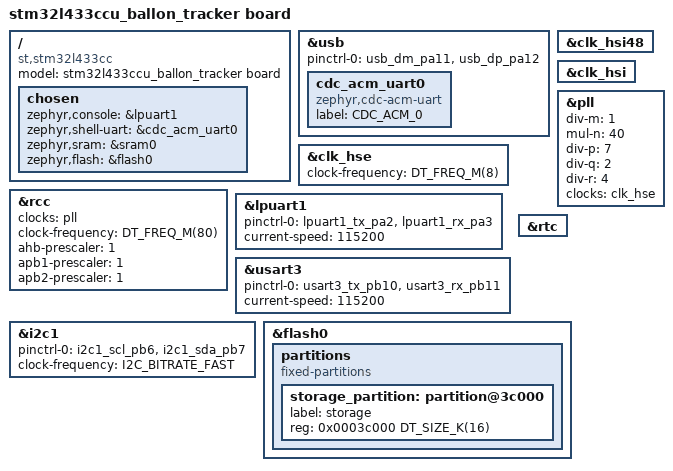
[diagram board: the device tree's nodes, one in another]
/*
 * Copyright (c) 2021 Matija Tudan
 *
 * SPDX-License-Identifier: Apache-2.0
 */

/dts-v1/;
#include <st/l4/stm32l433Xc.dtsi>
#include <st/l4/stm32l433c(b-c)ux-pinctrl.dtsi>

/ {
	model = "stm32l433ccu_ballon_tracker board";
	compatible = "st,stm32l433cc";

	chosen {
		zephyr,console = &lpuart1;
		zephyr,shell-uart = &cdc_acm_uart0;
		zephyr,sram = &sram0;
		zephyr,flash = &flash0;
	};
};

zephyr_udc0: &usb {
	pinctrl-0 = <&usb_dm_pa11 &usb_dp_pa12>;
	pinctrl-names = "default";
	status = "okay";
	cdc_acm_uart0: cdc_acm_uart0 {
		compatible = "zephyr,cdc-acm-uart";
		label = "CDC_ACM_0";
	};
};

&clk_hsi48 {
	status = "okay";
};

&clk_hsi {
	status = "okay";
};

&clk_hse {
	status = "okay";
	clock-frequency = <DT_FREQ_M(8)>;
};

&pll {
	div-m = <1>;
	mul-n = <40>;
	div-p = <7>;
	div-q = <2>;
	div-r = <4>;
	clocks = <&clk_hse>;
	status = "okay";
};

&rcc {
	clocks = <&pll>;
	clock-frequency = <DT_FREQ_M(80)>;
	ahb-prescaler = <1>;
	apb1-prescaler = <1>;
	apb2-prescaler = <1>;
};

&lpuart1 {
	pinctrl-0 = <&lpuart1_tx_pa2 &lpuart1_rx_pa3>;
	pinctrl-names = "default";
	current-speed = <115200>;
	status = "okay";
};

&usart3 {
	pinctrl-0 = <&usart3_tx_pb10 &usart3_rx_pb11>;
	pinctrl-names = "default";
	current-speed = <115200>;
};

&i2c1 {
	pinctrl-0 = <&i2c1_scl_pb6 &i2c1_sda_pb7>;
	pinctrl-names = "default";
	clock-frequency = <I2C_BITRATE_FAST>;
	status = "okay";
};

&rtc {
	status = "okay";
};

&flash0 {
	partitions {
		compatible = "fixed-partitions";
		#address-cells = <1>;
		#size-cells = <1>;

		/*
		 * Reserve the final 16 KiB for file system partition - future
		 */
		storage_partition: partition@3c000 {
			label = "storage";
			reg = <0x0003c000 DT_SIZE_K(16)>;
		};
	};
};
